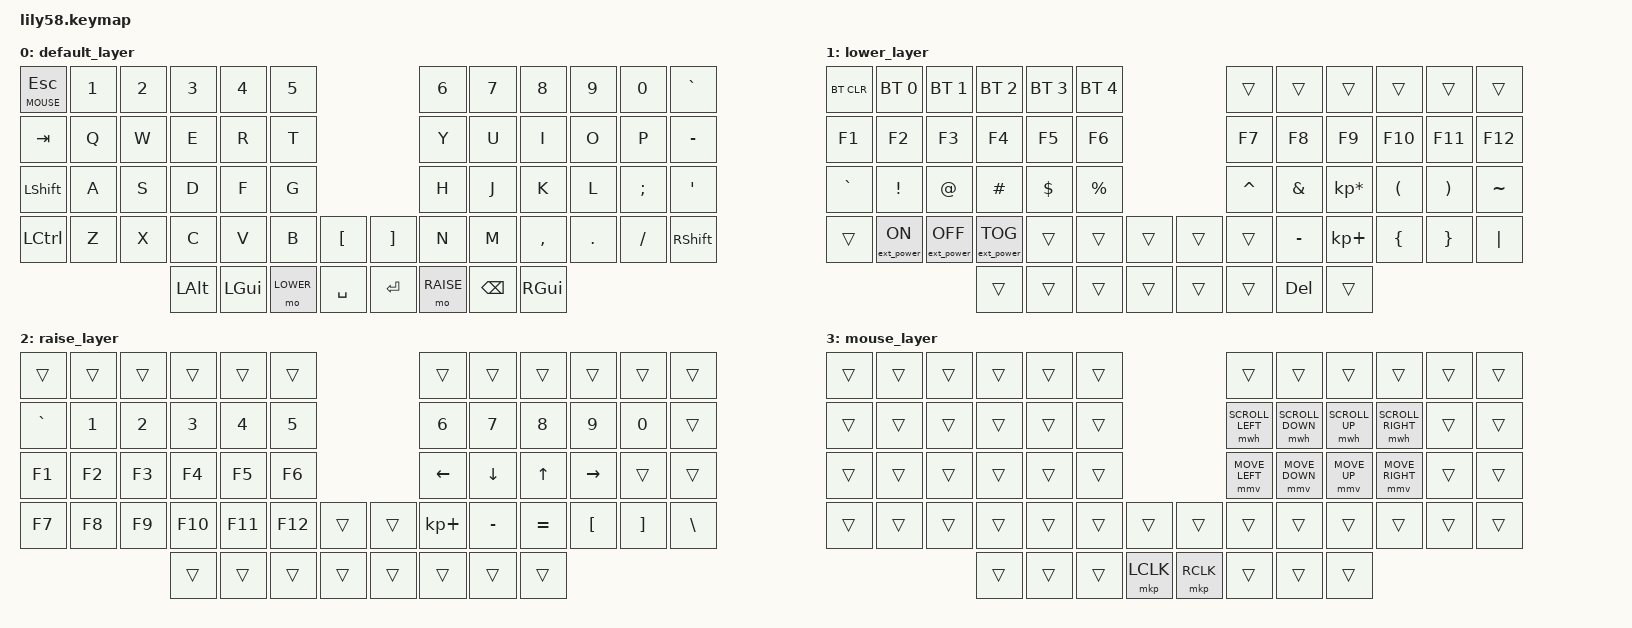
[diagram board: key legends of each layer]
#include <behaviors.dtsi>
#include <dt-bindings/zmk/keys.h>
#include <dt-bindings/zmk/bt.h>
#include <dt-bindings/zmk/ext_power.h>
#include <dt-bindings/zmk/mouse.h>

#define DEFAULT 0
#define LOWER 1
#define RAISE 2
#define MOUSE 3

#define MOUSE_TIME_TO_MAX_SPEED 500 

#define U_MOUSE_MOVE_MAX 3000
#undef MOVE_UP
#undef MOVE_DOWN
#undef MOVE_LEFT
#undef MOVE_RIGHT
#define MOVE_UP MOVE_VERT(-U_MOUSE_MOVE_MAX)
#define MOVE_DOWN MOVE_VERT(U_MOUSE_MOVE_MAX)
#define MOVE_LEFT MOVE_HOR(-U_MOUSE_MOVE_MAX)
#define MOVE_RIGHT MOVE_HOR(U_MOUSE_MOVE_MAX)

&mmv {
    time-to-max-speed-ms = <MOUSE_TIME_TO_MAX_SPEED>;
};

#define U_MOUSE_SCROLL_MAX 20 

#undef SCROLL_UP
#undef SCROLL_DOWN
#undef SCROLL_LEFT
#undef SCROLL_RIGHT
#define SCROLL_UP SCROLL_VERT(U_MOUSE_SCROLL_MAX)
#define SCROLL_DOWN SCROLL_VERT(-U_MOUSE_SCROLL_MAX)
#define SCROLL_LEFT SCROLL_HOR(-U_MOUSE_SCROLL_MAX)
#define SCROLL_RIGHT SCROLL_HOR(U_MOUSE_SCROLL_MAX)

&mwh {
    time-to-max-speed-ms = <MOUSE_TIME_TO_MAX_SPEED>;
};

/ {
	keymap {
		compatible = "zmk,keymap";

		default_layer {
// ------------------------------------------------------------------------------------------------------------------
// | ESC/MOUSE |  1  |  2  |  3   |  4   |  5   |                   |  6   |  7    |  8    |  9   |   0   |   `   |
// | TAB       |  Q  |  W  |  E   |  R   |  T   |                   |  Y   |  U    |  I    |  O   |   P   |   -   |
// | SHIFT     |  A  |  S  |  D   |  F   |  G   |                   |  H   |  J    |  K    |  L   |   ;   |   '   |
// | CTRL      |  Z  |  X  |  C   |  V   |  B   |   "["  |  |  "]"  |  N   |  M    |  ,    |  .   |   /   | SHIFT |
//                         | ALT  | GUI  | LOWER|  SPACE |  | ENTER | RAISE| BSPC  | GUI   |
			bindings = <
&lt MOUSE ESC &kp N1 &kp N2 &kp N3   &kp N4   &kp N5                        &kp N6    &kp N7   &kp N8    &kp N9  &kp N0   &kp GRAVE
&kp TAB       &kp Q  &kp W  &kp E    &kp R    &kp T                         &kp Y     &kp U    &kp I     &kp O   &kp P    &kp MINUS
&kp LSHFT     &kp A  &kp S  &kp D    &kp F    &kp G                         &kp H     &kp J    &kp K     &kp L   &kp SEMI &kp SQT
&kp LCTRL     &kp Z  &kp X  &kp C    &kp V    &kp B     &kp LBKT   &kp RBKT &kp N     &kp M    &kp COMMA &kp DOT &kp FSLH &kp RSHFT
                            &kp LALT &kp LGUI &mo LOWER &kp SPACE  &kp RET  &mo RAISE &kp BSPC &kp RGUI
			>;
		};

		lower_layer {
// ------------------------------------------------------------------------------------------------------------
// | BTCLR | BT1 | BT2 |  BT3 |  BT4 |  BT5 |                   |      |       |       |      |       |       |
// |  F1   |  F2 |  F3 |  F4  |  F5  |  F6  |                   |  F7  |  F8   |  F9   |  F10 |  F11  |  F12  |
// |   `   |  !  |  @  |  #   |  $   |  %   |                   |  ^   |  &    |  *    |  (   |   )   |   ~   |
// |       |     |     |      |      |      |        |  |       |      |  _    |  +    |  {   |   }   |  "|"  |
//                     |      |      |      |        |  |       |      |  DEL  |       |
			bindings = <
&bt BT_CLR &bt BT_SEL 0     &bt BT_SEL 1      &bt BT_SEL 2      &bt BT_SEL 3 &bt BT_SEL 4                 &trans    &trans    &trans          &trans    &trans    &trans
&kp F1     &kp F2           &kp F3            &kp F4            &kp F5       &kp F6                       &kp F7    &kp F8    &kp F9          &kp F10   &kp F11   &kp F12
&kp GRAVE  &kp EXCL         &kp AT            &kp HASH          &kp DOLLAR   &kp PRCNT                    &kp CARET &kp AMPS  &kp KP_MULTIPLY &kp LPAR  &kp RPAR  &kp TILDE
&trans     &ext_power EP_ON &ext_power EP_OFF &ext_power EP_TOG &trans       &trans    &trans   &trans    &trans    &kp MINUS &kp KP_PLUS     &kp LBRC  &kp RBRC  &kp PIPE
                                              &trans            &trans       &trans    &trans   &trans    &trans    &kp DEL    &trans
			>;
		};

		raise_layer {
// ------------------------------------------------------------------------------------------------------------
// |       |     |     |      |      |      |                   |      |       |       |      |       |       |
// |   `   |  1  |  2  |  3   |  4   |  5   |                   |  6   |   7   |   8   |  9   |   0   |       |
// |   F1  |  F2 |  F3 |  F4  |  F5  |  F6  |                   | <-   |   v   |   ^   |   -> |       |       |
// |   F7  |  F8 |  F9 |  F10 |  F11 |  F12 |        |  |       |  +   |   -   |   =   |  [   |   ]   |   \   |
//                     |      |      |      |        |  |       |      |       |       |
			bindings = <
&trans    &trans &trans &trans  &trans  &trans                       &trans      &trans    &trans    &trans    &trans    &trans
&kp GRAVE &kp N1 &kp N2 &kp N3  &kp N4  &kp N5                       &kp N6      &kp N7    &kp N8    &kp N9    &kp N0    &trans
&kp F1    &kp F2 &kp F3 &kp F4  &kp F5  &kp F6                       &kp LEFT    &kp DOWN  &kp UP    &kp RIGHT &trans    &trans
&kp F7    &kp F8 &kp F9 &kp F10 &kp F11 &kp F12   &trans   &trans    &kp KP_PLUS &kp MINUS &kp EQUAL &kp LBKT  &kp RBKT  &kp BSLH
                        &trans  &trans  &trans    &trans   &trans    &trans      &trans    &trans
			>;
		};

		mouse_layer {
// --------------------------------------------------------------------------------------------------------------------
// |       |     |     |      |      |      |                   |         |        |        |         |       |       |
// |       |     |     |      |      |      |                   | SCRL <- | SCRL v | SCRL ^ | SCRL -> |       |       |
// |       |     |     |      |      |      |                   |   <-    |    v   |    ^   |    ->   |       |       |
// |       |     |     |      |      |      |        |  |       |         |        |        |         |       |       |
//                     |      |      |      |  LCLK  |  | RCLK  |         |        |        |
			bindings = <
&trans &trans &trans &trans &trans &trans                     &trans           &trans           &trans         &trans            &trans &trans
&trans &trans &trans &trans &trans &trans                     &mwh SCROLL_LEFT &mwh SCROLL_DOWN &mwh SCROLL_UP &mwh SCROLL_RIGHT &trans &trans
&trans &trans &trans &trans &trans &trans                     &mmv MOVE_LEFT   &mmv MOVE_DOWN   &mmv MOVE_UP   &mmv MOVE_RIGHT   &trans &trans
&trans &trans &trans &trans &trans &trans &trans    &trans    &trans           &trans           &trans         &trans            &trans &trans
                     &trans &trans &trans &mkp LCLK &mkp RCLK &trans           &trans           &trans                     
			>;
		};

	};
};
